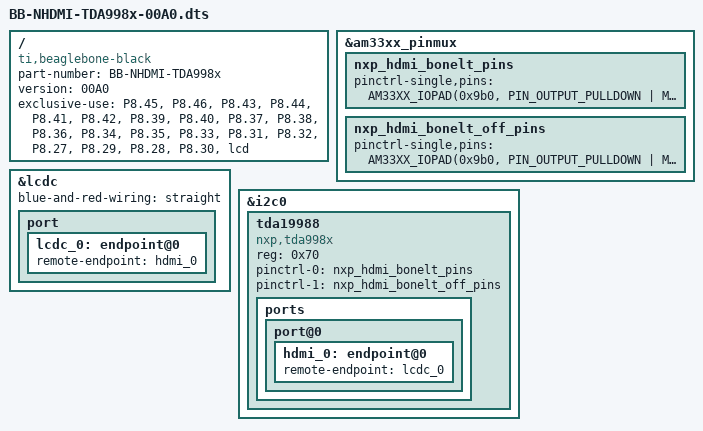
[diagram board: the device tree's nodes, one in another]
/*
* Copyright (C) 2012 Texas Instruments Incorporated - http://www.ti.com/
*
* This program is free software; you can redistribute it and/or modify
* it under the terms of the GNU General Public License version 2 as
* published by the Free Software Foundation.
*/
/dts-v1/;
/plugin/;

#include <dt-bindings/gpio/gpio.h>
#include <dt-bindings/pinctrl/am33xx.h>
#include <dt-bindings/display/tda998x.h>

/ {
	compatible = "ti,beaglebone-black";

	/* identification */
	part-number = "BB-NHDMI-TDA998x";
	version = "00A0";

	/* state the resources this cape uses */
	exclusive-use =
		/* the pin header uses */
		"P8.45",	/* lcd: lcd_data0 */
		"P8.46",	/* lcd: lcd_data1 */
		"P8.43",	/* lcd: lcd_data2 */
		"P8.44",	/* lcd: lcd_data3 */
		"P8.41",	/* lcd: lcd_data4 */
		"P8.42",	/* lcd: lcd_data5 */
		"P8.39",	/* lcd: lcd_data6 */
		"P8.40",	/* lcd: lcd_data7 */
		"P8.37",	/* lcd: lcd_data8 */
		"P8.38",	/* lcd: lcd_data9 */
		"P8.36",	/* lcd: lcd_data10 */
		"P8.34",	/* lcd: lcd_data11 */
		"P8.35",	/* lcd: lcd_data12 */
		"P8.33",	/* lcd: lcd_data13 */
		"P8.31",	/* lcd: lcd_data14 */
		"P8.32",	/* lcd: lcd_data15 */
		"P8.27",	/* lcd: lcd_vsync */
		"P8.29",	/* lcd: lcd_hsync */
		"P8.28",	/* lcd: lcd_pclk */
		"P8.30",	/* lcd: lcd_ac_bias_en */
		/* the hardware IP uses */
		"lcd";

	fragment@0 {
		target = <&am33xx_pinmux>;
		__overlay__ {
			nxp_hdmi_bonelt_pins: nxp_hdmi_bonelt_pins {
				pinctrl-single,pins = <
					AM33XX_IOPAD(0x9b0, PIN_OUTPUT_PULLDOWN | MUX_MODE3)	/* xdma_event_intr0 */
					AM33XX_IOPAD(0x8a0, PIN_OUTPUT | MUX_MODE0)		/* lcd_data0.lcd_data0 */
					AM33XX_IOPAD(0x8a4, PIN_OUTPUT | MUX_MODE0)		/* lcd_data1.lcd_data1 */
					AM33XX_IOPAD(0x8a8, PIN_OUTPUT | MUX_MODE0)		/* lcd_data2.lcd_data2 */
					AM33XX_IOPAD(0x8ac, PIN_OUTPUT | MUX_MODE0)		/* lcd_data3.lcd_data3 */
					AM33XX_IOPAD(0x8b0, PIN_OUTPUT | MUX_MODE0)		/* lcd_data4.lcd_data4 */
					AM33XX_IOPAD(0x8b4, PIN_OUTPUT | MUX_MODE0)		/* lcd_data5.lcd_data5 */
					AM33XX_IOPAD(0x8b8, PIN_OUTPUT | MUX_MODE0)		/* lcd_data6.lcd_data6 */
					AM33XX_IOPAD(0x8bc, PIN_OUTPUT | MUX_MODE0)		/* lcd_data7.lcd_data7 */
					AM33XX_IOPAD(0x8c0, PIN_OUTPUT | MUX_MODE0)		/* lcd_data8.lcd_data8 */
					AM33XX_IOPAD(0x8c4, PIN_OUTPUT | MUX_MODE0)		/* lcd_data9.lcd_data9 */
					AM33XX_IOPAD(0x8c8, PIN_OUTPUT | MUX_MODE0)		/* lcd_data10.lcd_data10 */
					AM33XX_IOPAD(0x8cc, PIN_OUTPUT | MUX_MODE0)		/* lcd_data11.lcd_data11 */
					AM33XX_IOPAD(0x8d0, PIN_OUTPUT | MUX_MODE0)		/* lcd_data12.lcd_data12 */
					AM33XX_IOPAD(0x8d4, PIN_OUTPUT | MUX_MODE0)		/* lcd_data13.lcd_data13 */
					AM33XX_IOPAD(0x8d8, PIN_OUTPUT | MUX_MODE0)		/* lcd_data14.lcd_data14 */
					AM33XX_IOPAD(0x8dc, PIN_OUTPUT | MUX_MODE0)		/* lcd_data15.lcd_data15 */
					AM33XX_IOPAD(0x8e0, PIN_OUTPUT_PULLDOWN | MUX_MODE0)	/* lcd_vsync.lcd_vsync */
					AM33XX_IOPAD(0x8e4, PIN_OUTPUT_PULLDOWN | MUX_MODE0)	/* lcd_hsync.lcd_hsync */
					AM33XX_IOPAD(0x8e8, PIN_OUTPUT_PULLDOWN | MUX_MODE0)	/* lcd_pclk.lcd_pclk */
					AM33XX_IOPAD(0x8ec, PIN_OUTPUT_PULLDOWN | MUX_MODE0)	/* lcd_ac_bias_en.lcd_ac_bias_en */
				>;
			};

			nxp_hdmi_bonelt_off_pins: nxp_hdmi_bonelt_off_pins {
				pinctrl-single,pins = <
					AM33XX_IOPAD(0x9b0, PIN_OUTPUT_PULLDOWN | MUX_MODE3)	/* xdma_event_intr0 */
				>;
			};
		};
	};

	fragment@1 {
		target = <&lcdc>;
		__overlay__ {
			status = "okay";

			/* If you want to get 24 bit RGB and 16 BGR mode instead of
			 * current 16 bit RGB and 24 BGR modes, set the propety
			 * below to "crossed" and uncomment the video-ports -property
			 * in tda19988 node.
			 */
			blue-and-red-wiring = "straight";

			port {
				lcdc_0: endpoint@0 {
					remote-endpoint = <&hdmi_0>;
				};
			};
		};
	};

	fragment@2 {
		target = <&i2c0>;
		__overlay__ {

			#address-cells = <1>;
			#size-cells = <0>;
			tda19988: tda19988 {
				compatible = "nxp,tda998x";
				reg = <0x70>;

				pinctrl-names = "default", "off";
				pinctrl-0 = <&nxp_hdmi_bonelt_pins>;
				pinctrl-1 = <&nxp_hdmi_bonelt_off_pins>;

				/* Convert 24bit BGR to RGB, e.g. cross red and blue wiring */
				/* video-ports = <0x234501>; */

				ports {
					port@0 {
						hdmi_0: endpoint@0 {
							remote-endpoint = <&lcdc_0>;
						};
					};
				};
			};
		};
	};
};
